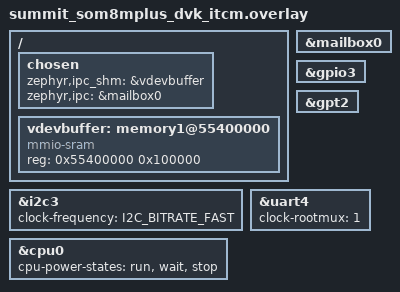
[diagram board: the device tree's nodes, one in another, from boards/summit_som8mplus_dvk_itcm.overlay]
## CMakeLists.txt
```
#
# Copyright (c) 2022 Laird Connectivity
#
# SPDX-License-Identifier: Apache-2.0
#

cmake_minimum_required(VERSION 3.20.0)

# Prepend the additional boards directory but still allow the original Zephyr
# boards directory to be used with lower priority
list(PREPEND BOARD_ROOT ${CMAKE_CURRENT_LIST_DIR}/../../)

set(modules_dir ${CMAKE_CURRENT_SOURCE_DIR}/../../modules)
set(rpmsg_lite_dir ${modules_dir}/rpmsg_lite)
set(MCUX_SDK_PROJECT_NAME app)

find_package(Zephyr REQUIRED HINTS $ENV{ZEPHYR_BASE})
project("Low Power Audio Example")

# Increase the SRTM I2C service buffer length (SRTM_I2C_BUF_LEN) to match the
# size configured in Linux. This was necessary to work around limitations of the
# RPMsg I2C driver in Linux that defaults to a buffer length of 16 bytes which
# is too small for some I2C devices.
add_compile_definitions(SRTM_I2C_BUF_LEN=128)

target_sources(app PRIVATE
	${rpmsg_lite_dir}/lib/common/llist.c
	${rpmsg_lite_dir}/lib/rpmsg_lite/rpmsg_lite.c
	${rpmsg_lite_dir}/lib/rpmsg_lite/rpmsg_ns.c
	${rpmsg_lite_dir}/lib/rpmsg_lite/rpmsg_queue.c
	${rpmsg_lite_dir}/lib/virtio/virtqueue.c
	${CMAKE_SOURCE_DIR}/src/main.c
	${CMAKE_SOURCE_DIR}/src/rsc_table.c
	${CMAKE_SOURCE_DIR}/src/rpmsg_env_zephyr.c
	${CMAKE_SOURCE_DIR}/src/rpmsg_platform.c
	${CMAKE_SOURCE_DIR}/src/lpm.c
	${CMAKE_SOURCE_DIR}/src/app_srtm.c
	${CMAKE_SOURCE_DIR}/src/srtm_heap_zephyr.c
	${CMAKE_SOURCE_DIR}/src/srtm_mutex_zephyr.c
	${CMAKE_SOURCE_DIR}/src/srtm_sem_zephyr.c

	# Pull in srtm_message_pool.c from the MCUX SDK since it isn't dependent on
	# FreeRTOS
	${modules_dir}/hal/nxp/mcux/mcux-sdk/components/srtm/port/srtm_message_pool.c

	# Workaround until the SAI SDMA driver is properly pulled in to the NXP HAL
	${modules_dir}/hal/nxp/mcux/mcux-sdk/drivers/sai/fsl_sai_sdma.c
	${modules_dir}/hal/nxp/mcux/mcux-sdk/drivers/sai/fsl_sai.c
	${modules_dir}/hal/nxp/mcux/mcux-sdk/drivers/sdma/fsl_sdma.c

	# Pull in SRTM services/channels
	${modules_dir}/hal/nxp/mcux/mcux-sdk/components/srtm/services/srtm_audio_service.c
	${modules_dir}/hal/nxp/mcux/mcux-sdk/components/srtm/services/srtm_sai_sdma_adapter.c
	${modules_dir}/hal/nxp/mcux/mcux-sdk/components/srtm/services/srtm_i2c_service.c
	${modules_dir}/hal/nxp/mcux/mcux-sdk/components/srtm/channels/srtm_rpmsg_endpoint.c
)

include_directories(
	${rpmsg_lite_dir}/lib/include
	${rpmsg_lite_dir}/lib/include/environment/zephyr
	${rpmsg_lite_dir}/lib/include/platform/imx8mp_m7
	${CMAKE_SOURCE_DIR}/include

	# Workaround until the SAI SDMA driver is properly pulled in to the NXP HAL
	${modules_dir}/hal/nxp/mcux/mcux-sdk/drivers/sai
	${modules_dir}/hal/nxp/mcux/mcux-sdk/drivers/sdma

	# Pull in SRTM services/channels
	${modules_dir}/hal/nxp/mcux/mcux-sdk/components/srtm/services
	${modules_dir}/hal/nxp/mcux/mcux-sdk/components/srtm/channels
)

# Include other MCUX drivers/components
include(${modules_dir}/hal/nxp/mcux/mcux-sdk/components/srtm/driver_srtm_MIMX8ML8.cmake)
```

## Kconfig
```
#
# Copyright (c) 2022 Laird Connectivity
#
# SPDX-License-Identifier: Apache-2.0
#

menu "Low Power Audio Example"

config RPMSG_LITE_RESOURCE_TABLE
	bool "coprocessor resource table"
	help
	  Add the resource table in the generated binary. This table is
	  compatible with linux remote proc framework and RPMsg-Lite library.

config RPMSG_LITE_IPC_DEV_NAME
	string "RPMsg-Lite IPC device name"
	default "MAILBOX_0"

config RPMSG_LITE_APP_STACKSIZE
	int "Application thread stack size"
	default 4096

endmenu

module = MAIN
module-str = MAIN
source "subsys/logging/Kconfig.template.log_config"

source "Kconfig.zephyr"
```

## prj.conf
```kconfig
CONFIG_RPMSG_LITE_RESOURCE_TABLE=y
CONFIG_IPM=y
CONFIG_HEAP_MEM_POOL_SIZE=16384
CONFIG_IPM_IMX_REV2=y
CONFIG_IPM_IMX_MAX_DATA_SIZE_4=y
CONFIG_HAVE_CUSTOM_LINKER_SCRIPT=y
CONFIG_CUSTOM_LINKER_SCRIPT="linker.ld"
CONFIG_I2C=y
CONFIG_I2C_MCUX_NONBLOCKING_TRANSFERS=y
CONFIG_PM=y
CONFIG_COUNTER=y
CONFIG_AUDIOMIX=y
CONFIG_M7_CLOCK_ROOT_SYSTEM_PLL1=y
CONFIG_AHB_CLOCK_ROOT_SYSTEM_PLL1_DIV6=y
CONFIG_PM_POLICY_APP=y
```

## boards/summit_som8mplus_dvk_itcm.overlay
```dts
/*
 * Copyright (c) 2022, Laird Connectivity
 *
 * SPDX-License-Identifier: Apache-2.0
 */

/ {
	chosen {
		/*
		 * shared memory reserved for the inter-processor communication
		 */
		zephyr,ipc_shm = &vdevbuffer;
		zephyr,ipc = &mailbox0;
	};

	vdevbuffer: memory1@55400000 {
		compatible = "mmio-sram";
		reg = <0x55400000 0x100000>;
	};
};

&mailbox0 {
	status = "okay";
};

&gpio3 {
	status = "okay";
};

&i2c3 {
	status = "okay";
	clock-frequency = <I2C_BITRATE_FAST>;
};

&gpt2 {
	status = "okay";
};

&uart4 {
	clock-rootmux = <1>;
};

&cpu0 {
	cpu-power-states = <&run &wait &stop>;
};
```

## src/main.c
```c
/*
 * Copyright (c) 2022 Laird Connectivity
 *
 * SPDX-License-Identifier: Apache-2.0
 */

#include <zephyr.h>
#include <drivers/gpio.h>
#include <drivers/clock_control.h>
#include <sys/printk.h>
#include <stdint.h>
#include <string.h>
#include <logging/log.h>
#include <pm/pm.h>

#include "rpmsg_lite.h"
#include "rpmsg_queue.h"
#include "rpmsg_ns.h"
#include "rsc_table.h"
#include "low_power_audio.h"
#include "lpm.h"
#include "fsl_audiomix.h"
#include "fsl_rdc.h"
#include "fsl_i2c.h"
#include "fsl_gpio.h"
#include "fsl_iomuxc.h"
#include "fsl_uart.h"
#include "app_srtm.h"

LOG_MODULE_REGISTER(main, LOG_LEVEL_DBG);

/*******************************************************************************
 * Definitions
 ******************************************************************************/
#define RDC_DISABLE_A53_ACCESS 0xFC
#define RDC_DISABLE_M7_ACCESS 0xF3
#define DOMAIN_ID (1U)
static lpm_power_status_m7_t m7_lpm_state = LPM_M7_STATE_RUN;
/* Using SRC_GPR10 register to sync the tasks status with A core */
#define ServiceFlagAddr SRC->GPR10
/*
 * The flags, ServiceBusy and ServiceIdle, shows if the service task is running or not. If the task
 * is running, A core should not put DDR in self-refresh mode after A core enters suspend.
 */
#define ServiceBusy (0x5555U)
#define ServiceIdle (0x0U)
#define SLEEP_TIME_MS 1
#define PM_MIN_TICKS 2
#define MAX_NUM_PLLS 39

/*******************************************************************************
 * Prototypes
 ******************************************************************************/
extern volatile app_srtm_state_t srtm_state;

/* Globals */
static struct k_thread app_thread;
K_THREAD_STACK_DEFINE(app_stack, CONFIG_RPMSG_LITE_APP_STACKSIZE);

/***** CODE *****/

/**
 * @brief Configure RDC
 *
 */
void rdc_configure_peripheral_access(void)
{
	rdc_domain_assignment_t assignment = { 0 };
	rdc_periph_access_config_t periph_config;

	assignment.domainId = DOMAIN_ID;

	/* Only configure the RDC if the RDC peripheral write access is allowed. */
	if ((0x1U & RDC_GetPeriphAccessPolicy(RDC, kRDC_Periph_RDC, assignment.domainId)) != 0U) {
		RDC_SetMasterDomainAssignment(RDC, kRDC_Master_SDMA3_PERIPH, &assignment);
		RDC_SetMasterDomainAssignment(RDC, kRDC_Master_SDMA3_BURST, &assignment);
		RDC_SetMasterDomainAssignment(RDC, kRDC_Master_SDMA3_SPBA2, &assignment);

		RDC_GetDefaultPeriphAccessConfig(&periph_config);
		/* Do not allow the A53 domain (domain0) to access the following peripherals */
		periph_config.policy = RDC_DISABLE_A53_ACCESS;
		periph_config.periph = kRDC_Periph_SAI3;
		RDC_SetPeriphAccessConfig(RDC, &periph_config);
		periph_config.periph = kRDC_Periph_UART4;
		RDC_SetPeriphAccessConfig(RDC, &periph_config);
		periph_config.periph = kRDC_Periph_GPT1;
		RDC_SetPeriphAccessConfig(RDC, &periph_config);
		periph_config.periph = kRDC_Periph_SDMA3;
		RDC_SetPeriphAccessConfig(RDC, &periph_config);
		periph_config.periph = kRDC_Periph_I2C3;
		RDC_SetPeriphAccessConfig(RDC, &periph_config);
	}
}

/**
 * @brief Configure pin mux for the SAI3 peripheral
 *
 */
void set_sai_pin_mux(void)
{
	IOMUXC_SetPinMux(IOMUXC_SAI3_MCLK_AUDIOMIX_SAI3_MCLK, 0U);
	IOMUXC_SetPinConfig(IOMUXC_SAI3_MCLK_AUDIOMIX_SAI3_MCLK,
			    IOMUXC_SW_PAD_CTL_PAD_DSE(3U) | IOMUXC_SW_PAD_CTL_PAD_FSEL_MASK |
				    IOMUXC_SW_PAD_CTL_PAD_PUE_MASK |
				    IOMUXC_SW_PAD_CTL_PAD_HYS_MASK);
	IOMUXC_SetPinMux(IOMUXC_SAI3_TXC_AUDIOMIX_SAI3_TX_BCLK, 0U);
	IOMUXC_SetPinConfig(IOMUXC_SAI3_TXC_AUDIOMIX_SAI3_TX_BCLK,
			    IOMUXC_SW_PAD_CTL_PAD_DSE(3U) | IOMUXC_SW_PAD_CTL_PAD_FSEL_MASK |
				    IOMUXC_SW_PAD_CTL_PAD_PUE_MASK |
				    IOMUXC_SW_PAD_CTL_PAD_HYS_MASK);
	IOMUXC_SetPinMux(IOMUXC_SAI3_TXD_AUDIOMIX_SAI3_TX_DATA0, 0U);
	IOMUXC_SetPinConfig(IOMUXC_SAI3_TXD_AUDIOMIX_SAI3_TX_DATA0,
			    IOMUXC_SW_PAD_CTL_PAD_DSE(3U) | IOMUXC_SW_PAD_CTL_PAD_FSEL_MASK |
				    IOMUXC_SW_PAD_CTL_PAD_PUE_MASK |
				    IOMUXC_SW_PAD_CTL_PAD_HYS_MASK);
	IOMUXC_SetPinMux(IOMUXC_SAI3_TXFS_AUDIOMIX_SAI3_TX_SYNC, 0U);
	IOMUXC_SetPinConfig(IOMUXC_SAI3_TXFS_AUDIOMIX_SAI3_TX_SYNC,
			    IOMUXC_SW_PAD_CTL_PAD_DSE(3U) | IOMUXC_SW_PAD_CTL_PAD_FSEL_MASK |
				    IOMUXC_SW_PAD_CTL_PAD_PUE_MASK |
				    IOMUXC_SW_PAD_CTL_PAD_HYS_MASK);
}

/**
 * @brief Set the M7 clock source between two supported modes: LOW - 24 MHz oscillator, HIGH -
 * SYSPLL1.
 *
 * @param target	Target clock speed
 */
void lpm_change_m7_clock(lpm_m7_clock_speed_t target)
{
	/* Change CCM Root to change M7 clock*/
	switch (target) {
	case LPM_M7_LOW_FREQ:
		if (CLOCK_GetRootMux(kCLOCK_RootM7) != kCLOCK_M7RootmuxOsc24M) {
			CLOCK_SetRootMux(kCLOCK_RootM7, kCLOCK_M7RootmuxOsc24M);
			CLOCK_SetRootDivider(kCLOCK_RootM7, 1U, 1U);
		}
		break;
	case LPM_M7_HIGH_FREQ:
		if (CLOCK_GetRootMux(kCLOCK_RootM7) != kCLOCK_M7RootmuxSysPll1) {
			CLOCK_SetRootDivider(kCLOCK_RootM7, 1U, 1U);
			/* switch cortex-m7 to SYSTEM PLL1 */
			CLOCK_SetRootMux(kCLOCK_RootM7, kCLOCK_M7RootmuxSysPll1);
		}
		break;
	default:
		break;
	}
}

/**
 * @brief Set the LPM mode
 *
 * @param target_power_mode	Target LPM mode
 */
void lpm_set_power_status(lpm_power_status_m7_t target_power_mode)
{
	gpc_lpm_config_t config;
	config.enCpuClk = false;
	config.enFastWakeUp = false;
	config.enDsmMask = false;
	config.enWfiMask = false;
	config.enVirtualPGCPowerdown = true;
	config.enVirtualPGCPowerup = true;
	switch (target_power_mode) {
	case LPM_M7_STATE_RUN:
		GPC->LPCR_M7 = GPC->LPCR_M7 & (~GPC_LPCR_M7_LPM0_MASK);
		break;
	case LPM_M7_STATE_WAIT:
		GPC_EnterWaitMode(GPC, &config);
		break;
	case LPM_M7_STATE_STOP:
		GPC_EnterStopMode(GPC, &config);
		break;
	default:
		break;
	}
}

/**
 * @brief Logic run before entering the LPM stop mode
 *
 */
void pre_sleep_processing(void)
{
	app_srtm_suspend();

	/* De-initialize the UART */
	UART_Deinit((UART_Type *)DT_REG_ADDR(DT_NODELABEL(uart4)));
}

/**
 * @brief Logic run after exiting the LPM stop mode
 *
 */
void post_sleep_processing(void)
{
	uart_config_t uart_config;
	uint32_t clock_freq;
	const struct device *clock_dev;
	clock_control_subsys_t clock_subsys;

	app_srtm_resume();

	/* Re-initialize the UART */
	clock_dev = DEVICE_DT_GET(DT_CLOCKS_CTLR(DT_NODELABEL(uart4)));
	clock_subsys = (clock_control_subsys_t)DT_CLOCKS_CELL(DT_NODELABEL(uart4), name);
	if (clock_control_get_rate(clock_dev, clock_subsys, &clock_freq) != 0) {
		clock_freq = 0;
	}

	UART_GetDefaultConfig(&uart_config);
	uart_config.enableTx = true;
	uart_config.enableRx = true;
	uart_config.baudRate_Bps = DT_PROP(DT_NODELABEL(uart4), current_speed);

	UART_Init((UART_Type *)DT_REG_ADDR(DT_NODELABEL(uart4)), &uart_config, clock_freq);
}

/**
 * @brief Print a message to the console about the current power mode
 *
 */
void show_m_core_status(void)
{
	switch (m7_lpm_state) {
	case LPM_M7_STATE_STOP:
		printk("M7 core entering STOP mode\n\n");
		break;
	case LPM_M7_STATE_WAIT:
		printk("M7 core entering WAIT mode\n\n");
		break;
	case LPM_M7_STATE_RUN:
		printk("M7 core entering RUN mode\n\n");
		break;
	default:
		/* Shouldn't happen */
		break;
	}
}

/**
 * @brief Update the target power mode based on the state of the SRTM service. If the mode changes,
 * print a message to the console.
 *
 */
void update_target_power_status(void)
{
	/*
	 * The m7_lpm_state merely indicates what the power state the M core finally should be. In
	 * this demo, if there is no audio playback, M core will be set to STOP mode finally.
	 */
	lpm_power_status_m7_t m7_target_lpm;

	if (app_srtm_service_idle()) {
		m7_target_lpm = LPM_M7_STATE_STOP;
	} else {
		m7_target_lpm = LPM_M7_STATE_RUN;
	}

	if (m7_target_lpm != m7_lpm_state) {
		m7_lpm_state = m7_target_lpm;
		show_m_core_status();
	}
}

/**
 * @brief Main app task function
 *
 * @param p1	Unused
 * @param p2	Unused
 * @param p3	Unused
 */
void app_task(void *p1, void *p2, void *p3)
{
	ARG_UNUSED(p1);
	ARG_UNUSED(p2);
	ARG_UNUSED(p3);

	lpm_increase_block_sleep_count();

	/* Treat M7 as busy status by default.*/
	ServiceFlagAddr = ServiceBusy;

	/*
	* Wait For A53 Side to Become Ready
	*/
	printk("Wait for Linux kernel to boot up and create the link between M core and A core\n");
	while (srtm_state != APP_SRTM_STATE_LINKED_UP)
		;
	printk("RPMsg channel created between M core and A core\n");

	printk("Main thread is now running\n");

	/* Small delay to let things settle */
	k_sleep(K_MSEC(1000));

	lpm_decrease_block_sleep_count();

	while (true) {
		k_sleep(K_FOREVER);
	}
}

/**
 * @brief Application-specific override of the Power Management set state function
 *
 * @param info	Info on the requested next state
 */
void pm_power_state_set(struct pm_state_info info)
{
	/* Extract target GPC mode from the substate ID */
	uint32_t target_mode = (uint32_t)info.substate_id;
	/* Read current GPC mode */
	uint32_t current_mode = GPC_GetLpmMode(GPC);

	irq_unlock(0);

	if (target_mode == current_mode) {
		__DSB();
		__ISB();
		__WFI();
		return;
	}

	switch (target_mode) {
	case kGPC_RunMode:
		lpm_set_power_status(LPM_M7_STATE_RUN);
		return;
	case kGPC_WaitMode:
		lpm_change_m7_clock(LPM_M7_LOW_FREQ);
		lpm_set_power_status(LPM_M7_STATE_WAIT);
		pre_sleep_processing();
		ServiceFlagAddr = ServiceIdle;

		__DSB();
		__ISB();
		__WFI();

		ServiceFlagAddr = ServiceBusy;
		post_sleep_processing();
		lpm_change_m7_clock(LPM_M7_HIGH_FREQ);
		lpm_set_power_status(LPM_M7_STATE_RUN);
		return;
	case kGPC_StopMode:
		lpm_change_m7_clock(LPM_M7_LOW_FREQ);
		lpm_set_power_status(LPM_M7_STATE_STOP);
		pre_sleep_processing();
		ServiceFlagAddr = ServiceIdle;

		__DSB();
		__ISB();
		__WFI();

		ServiceFlagAddr = ServiceBusy;
		post_sleep_processing();
		lpm_change_m7_clock(LPM_M7_HIGH_FREQ);
		lpm_set_power_status(LPM_M7_STATE_RUN);
		return;
	default:
		LOG_ERR("Unknown power state requested");
		return;
	}
}

/**
 * @brief Application-specific override of the Power Management power state exit handler function
 *
 * @param info	Info on the state that is currently being exited
 */
void pm_power_state_exit_post_ops(struct pm_state_info info)
{
	ARG_UNUSED(info);
}

/**
 * @brief Application-specific Power Management state management policy
 *
 * @param ticks			The number of remaining ticks before the system wakes
 * @return struct pm_state_info	Next power state
 */
struct pm_state_info pm_policy_next_state(int32_t ticks)
{
	update_target_power_status();

	/*
	 * If the available PM_MIN_TICKS is less than 2 or sleep isn't allowed, then just stay in
	 * the 'active' state. Otherwise, move to the 'stop' state.
	 */
	if (ticks >= PM_MIN_TICKS && app_srtm_service_idle() && lpm_allow_sleep()) {
		return (struct pm_state_info){ PM_STATE_SUSPEND_TO_IDLE, kGPC_StopMode, 0 };
	} else {
		return (struct pm_state_info){ PM_STATE_ACTIVE, kGPC_RunMode, 0 };
	}
}

/**
 * @brief Main application entry point
 *
 */
void main(void)
{
	uint32_t i = 0;

	lpm_increase_block_sleep_count();

	/* Enable the CCGR gate for SysPLL1 in Domain 1 */
	CLOCK_ControlGate(kCLOCK_SysPll1Gate, kCLOCK_ClockNeededAll);
	/* Enable the CCGR gate for SysPLL2 in Domain 1 */
	CLOCK_ControlGate(kCLOCK_SysPll2Gate, kCLOCK_ClockNeededAll);
	/* Enable the CCGR gate for SysPLL3 in Domain 1 */
	CLOCK_ControlGate(kCLOCK_SysPll3Gate, kCLOCK_ClockNeededAll);
	/* Enable the CCGR gate for AudioPLL1 in Domain 1 */
	CLOCK_ControlGate(kCLOCK_AudioPll1Gate, kCLOCK_ClockNeededAll);
	/* Enable the CCGR gate for AudioPLL2 in Domain 1 */
	CLOCK_ControlGate(kCLOCK_AudioPll2Gate, kCLOCK_ClockNeededAll);
	/* Enable the CCGR gate for VideoPLL1 in Domain 1 */
	CLOCK_ControlGate(kCLOCK_VideoPll1Gate, kCLOCK_ClockNeededAll);

	rdc_configure_peripheral_access();

	set_sai_pin_mux();

	/* Set SAI source to AUDIO PLL1 393216000HZ */
	CLOCK_SetRootMux(kCLOCK_RootSai3, kCLOCK_SaiRootmuxAudioPll1);
	/* Set root clock to 393216000HZ / 32 = 12.288MHz */
	CLOCK_SetRootDivider(kCLOCK_RootSai3, 1U, 32U);

	/*
	 * Enable the Audio clock on M7 side to make sure the AUDIOMIX domain clock on after A core
	 * enters suspend
	 */
	CLOCK_EnableClock(kCLOCK_Audio);
	/* SAI bit clock source */
	AUDIOMIX_AttachClk(AUDIOMIX, kAUDIOMIX_Attach_SAI3_MCLK1_To_SAI3_ROOT);

	/* In order to wakeup M7 from LPM, all PLLCTRLs need to be set to "NeededRun" */
	for (i = 0; i != MAX_NUM_PLLS; i++) {
		CCM->PLL_CTRL[i].PLL_CTRL = kCLOCK_ClockNeededRun;
	}

	printk("LOW POWER AUDIO TASK\n");
	printk("Build Time: %s--%s\n", __DATE__, __TIME__);

	app_srtm_init();

	k_thread_create(&app_thread, app_stack, CONFIG_RPMSG_LITE_APP_STACKSIZE, app_task, NULL,
			NULL, NULL, -1, K_USER, K_MSEC(0));

	lpm_decrease_block_sleep_count();

	while (true) {
		k_sleep(K_FOREVER);
	}
}
```

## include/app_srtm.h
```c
/*
 * Copyright 2020 NXP
 * Copyright 2022, Laird Connectivity
 * All rights reserved.
 *
 *
 * SPDX-License-Identifier: BSD-3-Clause
 */

#ifndef _APP_SRTM_H_
#define _APP_SRTM_H_

#include "rpmsg_lite.h"
#include "rsc_table.h"
#include "srtm_sem.h"

/*******************************************************************************
 * Definitions
 ******************************************************************************/
typedef enum {
	APP_SRTM_STATE_RUN = 0x0U,
	APP_SRTM_STATE_LINKED_UP,
} app_srtm_state_t;

#define APP_SRTM_SAI (I2S3)
#define APP_SRTM_SAI_IRQn I2S3_IRQn
#define APP_SRTM_DMA SDMAARM3
#define APP_SRTM_DMA_IRQn SDMA3_IRQn

/* The MCLK of the SAI is 12288000Hz by default which can be changed when playback the music. */
#define APP_SAI_CLK_FREQ (12288000U)
/* The frequency of the audio pll 1/2 are the fixed value. */
#define APP_AUDIO_PLL1_FREQ (393216000U)
#define APP_AUDIO_PLL2_FREQ (361267200U)
/* IRQ handler priority definition, bigger number stands for lower priority */
#define APP_SAI_TX_DMA_IRQ_PRIO (5U)
#define APP_SAI_RX_DMA_IRQ_PRIO (5U)
#define APP_SAI_IRQ_PRIO (5U)
/* Task priority definition, bigger number stands for higher priority */
#define APP_SRTM_MONITOR_TASK_PRIO -4
#define APP_SRTM_DISPATCHER_TASK_PRIO -3
/* SAI SDMA channel */
#define APP_SAI_TX_DMA_CHANNEL (1U)
#define APP_SAI_RX_DMA_CHANNEL (2U)
#define APP_SAI_RX_DMA_SOURCE (4U)
#define APP_SAI_TX_DMA_SOURCE (5U)
#define APP_SAI_TX_DMA_CHANNEL_PRIORITY (2U)
#define APP_SAI_RX_DMA_CHANNEL_PRIORITY (2U)

#define APP_I2C_SWITCH_NONE (1U) /* MAX SWITCH in this board is 1 */
#define APP_I2C_SWITCH_ADDR (0x71)
#define APP_I2C_BAUDRATE (400000U)

/* SAI and SDMA clock gate bit field in the AUDIOMIX */
/* SAI3 and SAI3_MCLK1 Must be both enabled in the AUDIOMIX */
#define APP_SAI_GATE (3 << 8U)
/* SDMA3 gate bit in the AUDIOMIX*/
#define APP_SDMA_GATE (1 << 27U)
/* Define the timeout ms to polling the CA7 link up status */
#define APP_LINKUP_TIMER_PERIOD_MS (10U)

#define RPMSG_LITE_SRTM_SHMEM_BASE (VDEV0_VRING_BASE)
#define RPMSG_LITE_SRTM_LINK_ID (0U)

#define APP_SRTM_AUDIO_CHANNEL_NAME "rpmsg-audio-channel"
#define APP_SRTM_I2C_CHANNEL_NAME "rpmsg-i2c-channel"

typedef void (*app_rpmsg_monitor_t)(struct rpmsg_lite_instance *rpmsg_handle, bool ready,
				    void *param);
typedef void (*app_irq_handler_t)(IRQn_Type irq, void *param);

/*******************************************************************************
 * API
 ******************************************************************************/

#if defined(__cplusplus)
extern "C" {
#endif

/* Initialize SRTM contexts */
void app_srtm_init(void);

/* Deinit SRTM service in suspend */
void app_srtm_suspend(void);

/* Restore SRTM service in resume */
void app_srtm_resume(void);

/* Set RPMsg channel init/deinit monitor */
void app_srtm_set_rpmsg_monitor(app_rpmsg_monitor_t monitor, void *param);

/* Set SNVS IRQ handler for application */
void app_srtm_set_irq_handler(app_irq_handler_t handler, void *param);

/* Check the SRTM services busy or idle.*/
bool app_srtm_service_idle(void);
#if defined(__cplusplus)
}
#endif

#endif /* _APP_SRTM_H_ */
```

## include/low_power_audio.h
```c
/*
 * Copyright (c) 2022 Laird Connectivity
 *
 * SPDX-License-Identifier: Apache-2.0
 */

#ifndef LOW_POWER_AUDIO_H
#define LOW_POWER_AUDIO_H

#include "fsl_gpc.h"

/*******************************************************************************
 * Definitions
 ******************************************************************************/

/* Shared memory base for RPMsg communication. */
#define VDEV0_VRING_BASE (0x55000000U)
#define RESOURCE_TABLE_OFFSET (0xFF000)

#define APP_PowerUpSlot (5U)
#define APP_PowerDnSlot (6U)

#define CODEC_I2C I2C3
#define CODEC_I2C_INSTANCE (3U)
#define CODEC_I2C_CLOCK_FREQ (16000000U)

/*
 * LPM state of M7 core
 */
typedef enum {
	LPM_M7_STATE_RUN,
	LPM_M7_STATE_WAIT,
	LPM_M7_STATE_STOP,
} lpm_power_status_m7_t;
/*
 * Clock Speed of M7 core
 */
typedef enum { LPM_M7_HIGH_FREQ, LPM_M7_LOW_FREQ } lpm_m7_clock_speed_t;

#endif // LOW_POWER_AUDIO_H
```

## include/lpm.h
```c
/*
 * Copyright 2020 NXP
 * Copyright 2022, Laird Connectivity
 * All rights reserved.
 *
 * SPDX-License-Identifier: BSD-3-Clause
 */

#ifndef _LPM_H_
#define _LPM_H_

#include "fsl_common.h"

/*******************************************************************************
 * Definitions
 ******************************************************************************/
#define SYSTICK_BASE    GPT1
#define SYSTICK_IRQn    GPT1_IRQn
#define SYSTICK_HANDLER GPT1_IRQHandler
#define SYSTICK_CLOCK \
    24000000 / (CLOCK_GetRootPreDivider(kCLOCK_RootGpt1)) / (CLOCK_GetRootPostDivider(kCLOCK_RootGpt1))

/*******************************************************************************
 * API
 ******************************************************************************/

#if defined(__cplusplus)
extern "C" {
#endif /* __cplusplus*/

/*!
 * @brief Configure the system tick(GPT) before entering the low power mode.
 * @return Return the sleep time ticks.
 */
uint32_t LPM_EnterTicklessIdle(uint32_t timeoutMilliSec, uint64_t *pCounter);
/*!
 * @brief Configure the system tick(GPT) after exist the low power mode.
 */
void LPM_ExitTicklessIdle(uint32_t timeoutTicks, uint64_t timeoutCounter);
/*!
 * @brief This function is used to increase the count of the block event.
 */
void LPM_IncreseBlockSleepCnt(void);
/*!
 * @brief This function is used to decrease the count of the block event.
 */
void LPM_DecreaseBlockSleepCnt(void);
/*!
 * @brief This function is used to judge if the system could enter low power mode.
 * @return Return true if there is no block event exists.
 */
bool LPM_AllowSleep(void);

void vPortSetupTimerInterrupt(void);
#if defined(__cplusplus)
}
#endif /* __cplusplus*/
#endif /* _LPM_H_ */
```

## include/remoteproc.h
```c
/*
 * Copyright (c) 2022 Laird Connectivity
 *
 * SPDX-License-Identifier: Apache-2.0
 */

#ifndef REMOTEPROC_H
#define REMOTEPROC_H

#include <stdint.h>

#if defined __cplusplus
extern "C" {
#endif

#define RSC_NOTIFY_ID_ANY 0xFFFFFFFFUL

#define RPROC_MAX_NAME_LEN 32

/* IAR ARM build tools */
#if defined(__ICCARM__)

#ifndef METAL_PACKED_BEGIN
#define METAL_PACKED_BEGIN __packed
#endif

#ifndef METAL_PACKED_END
#define METAL_PACKED_END
#endif

/* GNUC */
#elif defined(__GNUC__)

#ifndef METAL_PACKED_BEGIN
#define METAL_PACKED_BEGIN
#endif

#ifndef METAL_PACKED_END
#define METAL_PACKED_END __attribute__((__packed__))
#endif

/* ARMCC */
#elif defined(__CC_ARM) || defined(__ARMCC_VERSION)

#ifndef METAL_PACKED_BEGIN
#define METAL_PACKED_BEGIN _Pragma("pack(1U)")
#endif

#ifndef METAL_PACKED_END
#define METAL_PACKED_END _Pragma("pack()")
#endif

#else
/* There is no default definition here to avoid wrong structures packing in case of not supported compiler */
#error Please implement the structure packing macros for your compiler here!
#endif

/**
 * struct resource_table - firmware resource table header
 * @ver: version number
 * @num: number of resource entries
 * @reserved: reserved (must be zero)
 * @offset: array of offsets pointing at the various resource entries
 *
 * A resource table is essentially a list of system resources required
 * by the remote remoteproc. It may also include configuration entries.
 * If needed, the remote remoteproc firmware should contain this table
 * as a dedicated ".resource_table" ELF section.
 *
 * Some resources entries are mere announcements, where the host is informed
 * of specific remoteproc configuration. Other entries require the host to
 * do something (e.g. allocate a system resource). Sometimes a negotiation
 * is expected, where the firmware requests a resource, and once allocated,
 * the host should provide back its details (e.g. address of an allocated
 * memory region).
 *
 * The header of the resource table, as expressed by this structure,
 * contains a version number (should we need to change this format in the
 * future), the number of available resource entries, and their offsets
 * in the table.
 *
 * Immediately following this header are the resource entries themselves,
 * each of which begins with a resource entry header (as described below).
 */
METAL_PACKED_BEGIN
struct resource_table {
	uint32_t ver;
	uint32_t num;
	uint32_t reserved[2];
	uint32_t offset[0];
} METAL_PACKED_END;

/**
 * struct fw_rsc_hdr - firmware resource entry header
 * @type: resource type
 * @data: resource data
 *
 * Every resource entry begins with a 'struct fw_rsc_hdr' header providing
 * its @type. The content of the entry itself will immediately follow
 * this header, and it should be parsed according to the resource type.
 */
METAL_PACKED_BEGIN
struct fw_rsc_hdr {
	uint32_t type;
	uint8_t data[0];
} METAL_PACKED_END;

/**
 * enum fw_resource_type - types of resource entries
 *
 * @RSC_CARVEOUT:   request for allocation of a physically contiguous
 *          memory region.
 * @RSC_DEVMEM:     request to iommu_map a memory-based peripheral.
 * @RSC_TRACE:      announces the availability of a trace buffer into which
 *          the remote remoteproc will be writing logs.
 * @RSC_VDEV:       declare support for a virtio device, and serve as its
 *          virtio header.
 * @RSC_VENDOR_START: start of the vendor specific resource types range
 * @RSC_VENDOR_END  : end of the vendor specific resource types range
 * @RSC_LAST:       just keep this one at the end
 *
 * For more details regarding a specific resource type, please see its
 * dedicated structure below.
 *
 * Please note that these values are used as indices to the rproc_handle_rsc
 * lookup table, so please keep them sane. Moreover, @RSC_LAST is used to
 * check the validity of an index before the lookup table is accessed, so
 * please update it as needed.
 */
enum fw_resource_type {
	RSC_CARVEOUT = 0,
	RSC_DEVMEM = 1,
	RSC_TRACE = 2,
	RSC_VDEV = 3,
	RSC_LAST = 4,
	RSC_VENDOR_START = 128,
	RSC_VENDOR_END = 512,
};

#define FW_RSC_U64_ADDR_ANY 0xFFFFFFFFFFFFFFFFUL
#define FW_RSC_U32_ADDR_ANY 0xFFFFFFFFUL

/**
 * struct fw_rsc_carveout - physically contiguous memory request
 * @da: device address
 * @pa: physical address
 * @len: length (in bytes)
 * @flags: iommu protection flags
 * @reserved: reserved (must be zero)
 * @name: human-readable name of the requested memory region
 *
 * This resource entry requests the host to allocate a physically contiguous
 * memory region.
 *
 * These request entries should precede other firmware resource entries,
 * as other entries might request placing other data objects inside
 * these memory regions (e.g. data/code segments, trace resource entries, ...).
 *
 * Allocating memory this way helps utilizing the reserved physical memory
 * (e.g. CMA) more efficiently, and also minimizes the number of TLB entries
 * needed to map it (in case @rproc is using an IOMMU). Reducing the TLB
 * pressure is important; it may have a substantial impact on performance.
 *
 * If the firmware is compiled with static addresses, then @da should specify
 * the expected device address of this memory region. If @da is set to
 * FW_RSC_ADDR_ANY, then the host will dynamically allocate it, and then
 * overwrite @da with the dynamically allocated address.
 *
 * We will always use @da to negotiate the device addresses, even if it
 * isn't using an iommu. In that case, though, it will obviously contain
 * physical addresses.
 *
 * Some remote remoteprocs needs to know the allocated physical address
 * even if they do use an iommu. This is needed, e.g., if they control
 * hardware accelerators which access the physical memory directly (this
 * is the case with OMAP4 for instance). In that case, the host will
 * overwrite @pa with the dynamically allocated physical address.
 * Generally we don't want to expose physical addresses if we don't have to
 * (remote remoteprocs are generally _not_ trusted), so we might want to
 * change this to happen _only_ when explicitly required by the hardware.
 *
 * @flags is used to provide IOMMU protection flags, and @name should
 * (optionally) contain a human readable name of this carveout region
 * (mainly for debugging purposes).
 */
METAL_PACKED_BEGIN
struct fw_rsc_carveout {
	uint32_t type;
	uint32_t da;
	uint32_t pa;
	uint32_t len;
	uint32_t flags;
	uint32_t reserved;
	uint8_t name[RPROC_MAX_NAME_LEN];
} METAL_PACKED_END;

/**
 * struct fw_rsc_devmem - iommu mapping request
 * @da: device address
 * @pa: physical address
 * @len: length (in bytes)
 * @flags: iommu protection flags
 * @reserved: reserved (must be zero)
 * @name: human-readable name of the requested region to be mapped
 *
 * This resource entry requests the host to iommu map a physically contiguous
 * memory region. This is needed in case the remote remoteproc requires
 * access to certain memory-based peripherals; _never_ use it to access
 * regular memory.
 *
 * This is obviously only needed if the remote remoteproc is accessing memory
 * via an iommu.
 *
 * @da should specify the required device address, @pa should specify
 * the physical address we want to map, @len should specify the size of
 * the mapping and @flags is the IOMMU protection flags. As always, @name may
 * (optionally) contain a human readable name of this mapping (mainly for
 * debugging purposes).
 *
 * Note: at this point we just "trust" those devmem entries to contain valid
 * physical addresses, but this isn't safe and will be changed: eventually we
 * want remoteproc implementations to provide us ranges of physical addresses
 * the firmware is allowed to request, and not allow firmwares to request
 * access to physical addresses that are outside those ranges.
 */
METAL_PACKED_BEGIN
struct fw_rsc_devmem {
	uint32_t type;
	uint32_t da;
	uint32_t pa;
	uint32_t len;
	uint32_t flags;
	uint32_t reserved;
	uint8_t name[RPROC_MAX_NAME_LEN];
} METAL_PACKED_END;

/**
 * struct fw_rsc_trace - trace buffer declaration
 * @da: device address
 * @len: length (in bytes)
 * @reserved: reserved (must be zero)
 * @name: human-readable name of the trace buffer
 *
 * This resource entry provides the host information about a trace buffer
 * into which the remote remoteproc will write log messages.
 *
 * @da specifies the device address of the buffer, @len specifies
 * its size, and @name may contain a human readable name of the trace buffer.
 *
 * After booting the remote remoteproc, the trace buffers are exposed to the
 * user via debugfs entries (called trace0, trace1, etc..).
 */
METAL_PACKED_BEGIN
struct fw_rsc_trace {
	uint32_t type;
	uint32_t da;
	uint32_t len;
	uint32_t reserved;
	uint8_t name[RPROC_MAX_NAME_LEN];
} METAL_PACKED_END;

/**
 * struct fw_rsc_vdev_vring - vring descriptor entry
 * @da: device address
 * @align: the alignment between the consumer and producer parts of the vring
 * @num: num of buffers supported by this vring (must be power of two)
 * @notifyid is a unique rproc-wide notify index for this vring. This notify
 * index is used when kicking a remote remoteproc, to let it know that this
 * vring is triggered.
 * @reserved: reserved (must be zero)
 *
 * This descriptor is not a resource entry by itself; it is part of the
 * vdev resource type (see below).
 *
 * Note that @da should either contain the device address where
 * the remote remoteproc is expecting the vring, or indicate that
 * dynamically allocation of the vring's device address is supported.
 */
METAL_PACKED_BEGIN
struct fw_rsc_vdev_vring {
	uint32_t da;
	uint32_t align;
	uint32_t num;
	uint32_t notifyid;
	uint32_t reserved;
} METAL_PACKED_END;

/**
 * struct fw_rsc_vdev - virtio device header
 * @id: virtio device id (as in virtio_ids.h)
 * @notifyid is a unique rproc-wide notify index for this vdev. This notify
 * index is used when kicking a remote remoteproc, to let it know that the
 * status/features of this vdev have changes.
 * @dfeatures specifies the virtio device features supported by the firmware
 * @gfeatures is a place holder used by the host to write back the
 * negotiated features that are supported by both sides.
 * @config_len is the size of the virtio config space of this vdev. The config
 * space lies in the resource table immediate after this vdev header.
 * @status is a place holder where the host will indicate its virtio progress.
 * @num_of_vrings indicates how many vrings are described in this vdev header
 * @reserved: reserved (must be zero)
 * @vring is an array of @num_of_vrings entries of 'struct fw_rsc_vdev_vring'.
 *
 * This resource is a virtio device header: it provides information about
 * the vdev, and is then used by the host and its peer remote remoteprocs
 * to negotiate and share certain virtio properties.
 *
 * By providing this resource entry, the firmware essentially asks remoteproc
 * to statically allocate a vdev upon registration of the rproc (dynamic vdev
 * allocation is not yet supported).
 *
 * Note: unlike virtualization systems, the term 'host' here means
 * the Linux side which is running remoteproc to control the remote
 * remoteprocs. We use the name 'gfeatures' to comply with virtio's terms,
 * though there isn't really any virtualized guest OS here: it's the host
 * which is responsible for negotiating the final features.
 * Yeah, it's a bit confusing.
 *
 * Note: immediately following this structure is the virtio config space for
 * this vdev (which is specific to the vdev; for more info, read the virtio
 * spec). the size of the config space is specified by @config_len.
 */
METAL_PACKED_BEGIN
struct fw_rsc_vdev {
	uint32_t type;
	uint32_t id;
	uint32_t notifyid;
	uint32_t dfeatures;
	uint32_t gfeatures;
	uint32_t config_len;
	uint8_t status;
	uint8_t num_of_vrings;
	uint8_t reserved[2];
	struct fw_rsc_vdev_vring vring[0];
} METAL_PACKED_END;

/**
 * struct fw_rsc_vendor - remote processor vendor specific resource
 * @len: length of the resource
 *
 * This resource entry tells the host the vendor specific resource
 * required by the remote.
 *
 * These request entries should precede other shared resource entries
 * such as vdevs, vrings.
 */
METAL_PACKED_BEGIN
struct fw_rsc_vendor {
	uint32_t type;
	uint32_t len;
} METAL_PACKED_END;

#if defined __cplusplus
}
#endif

#endif /* REMOTEPROC_H_ */
```

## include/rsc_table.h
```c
/*
 * Copyright (c) 2022 Laird Connectivity
 *
 * SPDX-License-Identifier: Apache-2.0
 */

/* This file populates resource table for BM remote
 * for use by the Linux Master */

#ifndef RSC_TABLE_H_
#define RSC_TABLE_H_

#include "low_power_audio.h"
#include <stddef.h>
#include <remoteproc.h>

#if defined __cplusplus
extern "C" {
#endif

#define NO_RESOURCE_ENTRIES (1)
#define RSC_VDEV_FEATURE_NS (1) /* Support name service announcement */

/* Resource table for the given remote */
METAL_PACKED_BEGIN
struct remote_resource_table {
	uint32_t version;
	uint32_t num;
	uint32_t reserved[2];
	uint32_t offset[NO_RESOURCE_ENTRIES];

	/* rpmsg vdev entry for user app communication */
	struct fw_rsc_vdev user_vdev;
	struct fw_rsc_vdev_vring user_vring0;
	struct fw_rsc_vdev_vring user_vring1;
} METAL_PACKED_END;

/*
 * Copy resource table to shared memory base for early M4 boot case.
 * In M4 early boot case, Linux kernel need to get resource table before file system gets loaded.
 */
void copy_resource_table(void);

#if defined __cplusplus
}
#endif

#endif /* RSC_TABLE_H_ */
```

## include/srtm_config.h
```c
/*
 * Copyright 2022, Laird Connectivity
 * All rights reserved.
 *
 *
 * SPDX-License-Identifier: Apache-2.0
 */

#ifndef _SRTM_CONFIG_H
#define _SRTM_CONFIG_H

#include "zephyr.h"

#endif
```

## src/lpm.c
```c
/*
 * Copyright 2020 NXP
 * Copyright 2022, Laird Connectivity
 * All rights reserved.
 *
 * SPDX-License-Identifier: BSD-3-Clause
 */

#include <zephyr.h>
#include "lpm.h"
#include <drivers/timer/system_timer.h>
#include "fsl_gpt.h"
/*******************************************************************************
 * Definitions
 ******************************************************************************/
/* Systick counter source clock frequency. Need config the Systick counter's(GPT) clock
 * source to this frequency in application.
 */
#define SYSTICK_COUNTER_SOURCE_CLK_FREQ (SYSTICK_CLOCK)
/* Define the counter clock of the systick (GPT).*/
#define SYSTICK_COUNTER_FREQ (8000000U)
/* Define the count per tick of the systick in run mode. For accuracy purpose,
 * please make SYSTICK_SOURCE_CLOCK times of configTICK_RATE_HZ.
 */
#define configTICK_RATE_HZ  200
#define SYSTICK_COUNT_PER_TICK (SYSTICK_COUNTER_FREQ / configTICK_RATE_HZ)


/* If block envent exists, then do not allow M7 to enter low power mode.*/
static uint32_t s_BlockEventCnt = 0;

extern void GPT1_IRQHandler();
extern void sys_clock_isr(void *arg);

/*******************************************************************************
 * Code
 ******************************************************************************/
/* Override the default definition of vPortSetupTimerInterrupt() that is weakly
 * defined in the FreeRTOS Cortex-M7F port layer with a version that configures
 * GPT to generate the tick interrupt. */
void vPortSetupTimerInterrupt(void)
{
    gpt_config_t config;
    GPT_GetDefaultConfig(&config);
    config.enableRunInDoze = true;
    config.clockSource     = kGPT_ClockSource_Osc;

    /* Initialize timer */
    GPT_Init(SYSTICK_BASE, &config);
    /* Divide GPT clock source frequency to SYSTICK_COUNTER_FREQ */
    GPT_SetOscClockDivider(SYSTICK_BASE, SYSTICK_COUNTER_SOURCE_CLK_FREQ / SYSTICK_COUNTER_FREQ);

    /* Set timer period */
    GPT_SetOutputCompareValue(SYSTICK_BASE, kGPT_OutputCompare_Channel1, SYSTICK_COUNT_PER_TICK - 1U);
    /* Enable timer interrupt */
    GPT_EnableInterrupts(SYSTICK_BASE, kGPT_OutputCompare1InterruptEnable);

    IRQ_CONNECT(SYSTICK_IRQn, IRQ_PRIO_LOWEST,
                SYSTICK_HANDLER, NULL, 0);
    /* Enable NVIC interrupt */
    NVIC_EnableIRQ(SYSTICK_IRQn);
    /* Start counting */
    GPT_StartTimer(SYSTICK_BASE);
}

uint32_t LPM_EnterTicklessIdle(uint32_t timeoutMilliSec, uint64_t *pCounter)
{
    uint32_t counter, expired = 0;
    uint32_t ms, maxMS;
    uint32_t flag;
    uint32_t timeoutTicks;
    uint32_t countPerTick = SYSTICK_COUNT_PER_TICK;

    /* If timeout < 2 ticks, don't do tickless idle. */
    if ((uint64_t)timeoutMilliSec * configTICK_RATE_HZ < 2 * 1000)
    {
        return 0;
    }

    maxMS = 0xFFFFFFFFU / SYSTICK_COUNTER_FREQ * 1000;
    ms    = timeoutMilliSec > maxMS ? maxMS : timeoutMilliSec;

    /* Calculate the timer counter needed for timeout */
    timeoutTicks = (uint64_t)ms * configTICK_RATE_HZ / 1000;
    counter      = timeoutTicks * countPerTick;

    GPT_StopTimer(SYSTICK_BASE); /* Timer stopped. */
    flag = GPT_GetStatusFlags(SYSTICK_BASE, kGPT_OutputCompare1Flag);
    if (flag)
    {
        GPT_ClearStatusFlags(SYSTICK_BASE, kGPT_OutputCompare1Flag);
        NVIC_ClearPendingIRQ(SYSTICK_IRQn);
        expired = countPerTick;
    }
    expired += GPT_GetCurrentTimerCount(SYSTICK_BASE);
    /* Minus those already expired to get accurate waiting counter. */
    counter -= expired;

    /* Enable GPT free-run mode, the counter is not reset when compare events occur.
     * In this way, the counter is not overflow during tickless and the exact time
     * since tickless enter can be calculated.
     */
    SYSTICK_BASE->CR |= GPT_CR_FRR_MASK;
    /* Convert count in systick freq to tickless clock count */
    GPT_SetOutputCompareValue(SYSTICK_BASE, kGPT_OutputCompare_Channel1, counter - 1UL);
    /* Restart timer, GPT CR_ENMOD=1, counter value is reset when restart timer. */
    GPT_StartTimer(SYSTICK_BASE);

    /* return waiting counter */
    *pCounter = counter;

    return timeoutTicks;
}

void LPM_ExitTicklessIdle(uint32_t timeoutTicks, uint64_t timeoutCounter)
{
    uint32_t flag, counter, expired, expiredTicks;
    uint32_t completeTicks;
    uint32_t countPerTick = SYSTICK_COUNT_PER_TICK;

    GPT_StopTimer(SYSTICK_BASE);
    flag = GPT_GetStatusFlags(SYSTICK_BASE, kGPT_OutputCompare1Flag);
    /* Convert tickless count to systick count. */
    expired = GPT_GetCurrentTimerCount(SYSTICK_BASE);

    if (flag)
    {
        /* If counter already exceeds 1 tick, it means wakeup takes too much time
         * and we have already lost some ticks. Calcaute and add the
         * lost ticks into completeTicks. Completed ticks minus 1 because pending interrupt will be handled immediately
         * when interrupt unmasked.
         */
        expiredTicks  = (expired - timeoutCounter) / countPerTick;
        completeTicks = expiredTicks + timeoutTicks - 1;

        /* Continue the uncompleted tick. */
        counter = countPerTick - (expired - timeoutCounter) % countPerTick;
    }
    else
    {
        /* Remaining counter. */
        counter       = timeoutCounter - expired;
        completeTicks = timeoutTicks - (counter - 1) / countPerTick - 1;
        counter       = (counter - 1) % countPerTick + 1;
    }

    /* Now reinit Systick. */
    SYSTICK_BASE->CR &= ~GPT_CR_FRR_MASK;
    GPT_SetOutputCompareValue(SYSTICK_BASE, kGPT_OutputCompare_Channel1, counter - 1UL);
    /* Restart timer */
    GPT_StartTimer(SYSTICK_BASE);

    sys_clock_announce(completeTicks);
}

/* The systick interrupt handler. */
void SYSTICK_HANDLER(void)
{
    /* Clear interrupt flag.*/
    GPT_ClearStatusFlags(SYSTICK_BASE, kGPT_OutputCompare1Flag);

    /* This is the first tick since the MCU left a low power mode the
     * compare value need to be reset to its default.
     */
    if (GPT_GetOutputCompareValue(SYSTICK_BASE, kGPT_OutputCompare_Channel1) != SYSTICK_COUNT_PER_TICK - 1)
    {
        /* Counter will be reset and cause minor accuracy loss */
        GPT_SetOutputCompareValue(SYSTICK_BASE, kGPT_OutputCompare_Channel1, SYSTICK_COUNT_PER_TICK - 1);
    }

    /* Call Zephyr tick handler. */
    sys_clock_isr(NULL);

    /* Add for ARM errata 838869, affects Cortex-M7, Cortex-M7F Store immediate overlapping
    exception return operation might vector to incorrect interrupt */
    __DSB();
}

void LPM_IncreseBlockSleepCnt(void)
{
    s_BlockEventCnt++;
}

void LPM_DecreaseBlockSleepCnt(void)
{
    s_BlockEventCnt--;
}

bool LPM_AllowSleep(void)
{
    if (s_BlockEventCnt)
    {
        return false;
    }
    else
    {
        return true;
    }
}
```

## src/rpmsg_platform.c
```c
/*
 * Copyright 2019-2020 NXP
 * Copyright (c) 2022 Laird Connectivity
 * All rights reserved.
 *
 *
 * SPDX-License-Identifier: BSD-3-Clause
 */

#include <zephyr.h>
#include <stdio.h>
#include <string.h>
#include "rpmsg_platform.h"
#include "rpmsg_env.h"

#include "fsl_device_registers.h"
#include "fsl_mu.h"
#include "irq.h"
#include <drivers/ipm.h>
#include <logging/log.h>
LOG_MODULE_REGISTER(rpmsg_platform, LOG_LEVEL_DBG);

#if defined(RL_USE_ENVIRONMENT_CONTEXT) && (RL_USE_ENVIRONMENT_CONTEXT == 1)
#error "This RPMsg-Lite port requires RL_USE_ENVIRONMENT_CONTEXT set to 0"
#endif

#if !DT_HAS_CHOSEN(zephyr_ipc_shm)
#error "Sample requires definition of shared memory for rpmsg"
#endif

static int32_t isr_counter     = 0;
static int32_t disable_counter = 0;
static void *platform_lock;
static const struct device *ipm_handle;

static void platform_global_isr_disable(void)
{
    __asm volatile("cpsid i");
}

static void platform_global_isr_enable(void)
{
    __asm volatile("cpsie i");
}

int32_t platform_init_interrupt(uint32_t vector_id, void *isr_data)
{
    /* Register ISR to environment layer */
    env_register_isr(vector_id, isr_data);

    /* Prepare the MU Hardware, enable channel 1 interrupt */
    env_lock_mutex(platform_lock);

    RL_ASSERT(0 <= isr_counter);
    if (isr_counter == 0)
    {
        ipm_set_enabled(ipm_handle, 1);
    }
    isr_counter++;

    env_unlock_mutex(platform_lock);

    return 0;
}

int32_t platform_deinit_interrupt(uint32_t vector_id)
{
    /* Prepare the MU Hardware */
    env_lock_mutex(platform_lock);

    RL_ASSERT(0 < isr_counter);
    isr_counter--;
    if (isr_counter == 0)
    {
        ipm_set_enabled(ipm_handle, 0);
    }

    /* Unregister ISR from environment layer */
    env_unregister_isr(vector_id);

    env_unlock_mutex(platform_lock);

    return 0;
}

void platform_notify(uint32_t vector_id)
{
    /* As Linux suggests, use MU->Data Channel 1 as communication channel */
    uint32_t msg = (uint32_t)(vector_id << 16);
    int ret = 0;

    env_lock_mutex(platform_lock);

    ret = ipm_send(ipm_handle, 0, RPMSG_MU_CHANNEL, &msg, 1);
    if (ret != 0) {
        LOG_WRN("ipm_send failed! ret: %d", ret);
    }

    env_unlock_mutex(platform_lock);
}

/*
 * MU Interrrupt RPMsg handler
 */
void MU1_M7_IRQHandler(const struct device *dev, void *context,
				  uint32_t id, volatile void *data)
{
    uint32_t *data32 = (uint32_t *)data;

    // Call the environment ISR
    env_isr(data32[0] >> 16);
}

/**
 * platform_time_delay
 *
 * @param num_msec Delay time in ms.
 *
 * This is not an accurate delay, it ensures at least num_msec passed when return.
 */
void platform_time_delay(uint32_t num_msec)
{
    uint32_t loop;

    /* Recalculate the CPU frequency */
    SystemCoreClockUpdate();

    /* Calculate the CPU loops to delay, each loop has 3 cycles */
    loop = SystemCoreClock / 3U / 1000U * num_msec;

    /* There's some difference among toolchains, 3 or 4 cycles each loop */
    while (loop > 0U)
    {
        __NOP();
        loop--;
    }
}

/**
 * platform_in_isr
 *
 * Return whether CPU is processing IRQ
 *
 * @return True for IRQ, false otherwise.
 *
 */
int32_t platform_in_isr(void)
{
    return (((SCB->ICSR & SCB_ICSR_VECTACTIVE_Msk) != 0UL) ? 1 : 0);
}

/**
 * platform_interrupt_enable
 *
 * Enable peripheral-related interrupt
 *
 * @param vector_id Virtual vector ID that needs to be converted to IRQ number
 *
 * @return vector_id Return value is never checked.
 *
 */
int32_t platform_interrupt_enable(uint32_t vector_id)
{
    RL_ASSERT(0 < disable_counter);

    platform_global_isr_disable();
    disable_counter--;

    if (disable_counter == 0)
    {
        irq_enable(MU1_M7_IRQn);
    }
    platform_global_isr_enable();
    return ((int32_t)vector_id);
}

/**
 * platform_interrupt_disable
 *
 * Disable peripheral-related interrupt.
 *
 * @param vector_id Virtual vector ID that needs to be converted to IRQ number
 *
 * @return vector_id Return value is never checked.
 *
 */
int32_t platform_interrupt_disable(uint32_t vector_id)
{
    RL_ASSERT(0 <= disable_counter);

    platform_global_isr_disable();
    /* virtqueues use the same NVIC vector
       if counter is set - the interrupts are disabled */
    if (disable_counter == 0)
    {
        irq_disable(MU1_M7_IRQn);
    }
    disable_counter++;
    platform_global_isr_enable();
    return ((int32_t)vector_id);
}

/**
 * platform_map_mem_region
 *
 * Dummy implementation
 *
 */
void platform_map_mem_region(uint32_t vrt_addr, uint32_t phy_addr, uint32_t size, uint32_t flags)
{
}

/**
 * platform_cache_all_flush_invalidate
 *
 * Dummy implementation
 *
 */
void platform_cache_all_flush_invalidate(void)
{
}

/**
 * platform_cache_disable
 *
 * Dummy implementation
 *
 */
void platform_cache_disable(void)
{
}

/**
 * platform_vatopa
 *
 * Dummy implementation
 *
 */
uint32_t platform_vatopa(void *addr)
{
    return ((uint32_t)(char *)addr);
}

/**
 * platform_patova
 *
 * Dummy implementation
 *
 */
void *platform_patova(uint32_t addr)
{
    return ((void *)(char *)addr);
}

/**
 * platform_init
 *
 * platform/environment init
 */
int32_t platform_init(void)
{
	/* setup IPM */
	ipm_handle = device_get_binding(CONFIG_RPMSG_LITE_IPC_DEV_NAME);
	if (!ipm_handle) {
		LOG_ERR("%s: Failed to find ipm device", __func__);
		return -1;
	}
	if (!device_is_ready(ipm_handle)) {
		while (1) {
		}
	}

    ipm_register_callback(ipm_handle, MU1_M7_IRQHandler, NULL);

    /* Create lock used in multi-instanced RPMsg */
    if (0 != env_create_mutex(&platform_lock, 1))
    {
        return -1;
    }

    return 0;
}

/**
 * platform_deinit
 *
 * platform/environment deinit process
 */
int32_t platform_deinit(void)
{
    /* Delete lock used in multi-instanced RPMsg */
    env_delete_mutex(platform_lock);
    platform_lock = ((void *)0);
    return 0;
}
```
